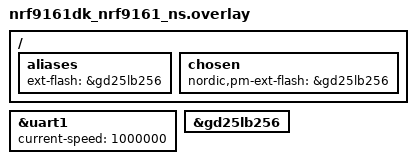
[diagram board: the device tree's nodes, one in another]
/*
 * Copyright (c) 2022 Nordic Semiconductor ASA
 *
 * SPDX-License-Identifier: LicenseRef-Nordic-5-Clause
 */


/ {
	aliases {
		ext-flash = &gd25lb256;
	};

	/* Configure partition manager to use gd25lb256 as the external flash */
	chosen {
		nordic,pm-ext-flash = &gd25lb256;
	};
};

/* Enable UART1 at 1 megabaud for printing modem traces  */
&uart1 {
	status = "okay";
	current-speed = <1000000>;
};

&gd25lb256 {
	status = "okay";
};

